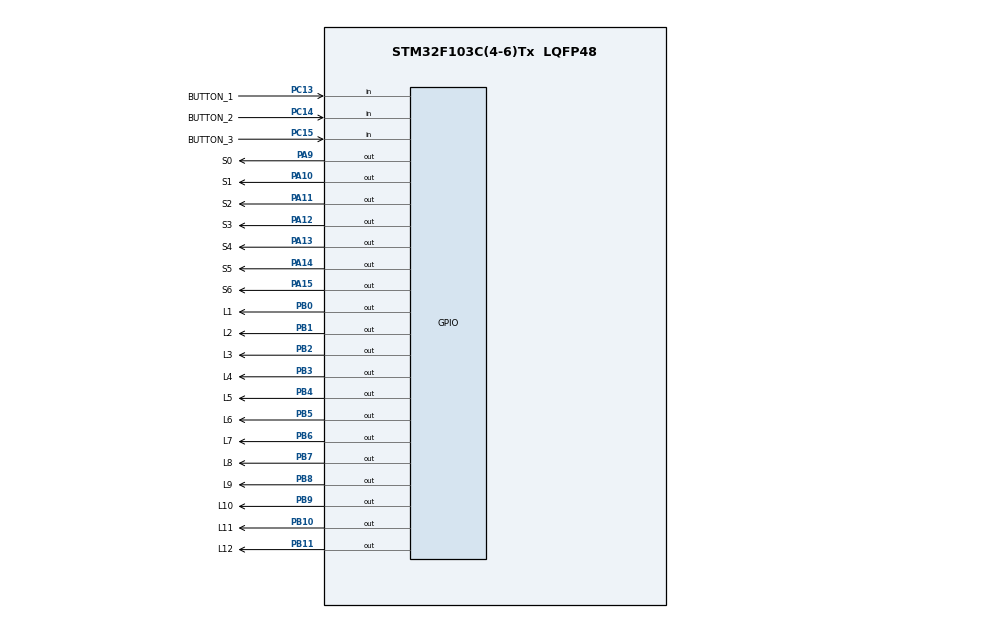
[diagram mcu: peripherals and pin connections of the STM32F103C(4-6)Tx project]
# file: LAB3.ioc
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Mcu.Family=STM32F1
Mcu.Name=STM32F103C(4-6)Tx
Mcu.Package=LQFP48
NVIC.PriorityGroup=NVIC_PRIORITYGROUP_4
PA10.GPIO_Label=S1
PA10.Signal=GPIO_Output
PA11.GPIO_Label=S2
PA11.Signal=GPIO_Output
PA12.GPIO_Label=S3
PA12.Signal=GPIO_Output
PA13.GPIO_Label=S4
PA13.Signal=GPIO_Output
PA14.GPIO_Label=S5
PA14.Signal=GPIO_Output
PA15.GPIO_Label=S6
PA15.Signal=GPIO_Output
PA9.GPIO_Label=S0
PA9.Signal=GPIO_Output
PB0.GPIO_Label=L1
PB0.Signal=GPIO_Output
PB1.GPIO_Label=L2
PB1.Signal=GPIO_Output
PB10.GPIO_Label=L11
PB10.Signal=GPIO_Output
PB11.GPIO_Label=L12
PB11.Signal=GPIO_Output
PB2.GPIO_Label=L3
PB2.Signal=GPIO_Output
PB3.GPIO_Label=L4
PB3.Signal=GPIO_Output
PB4.GPIO_Label=L5
PB4.Signal=GPIO_Output
PB5.GPIO_Label=L6
PB5.Signal=GPIO_Output
PB6.GPIO_Label=L7
PB6.Signal=GPIO_Output
PB7.GPIO_Label=L8
PB7.Signal=GPIO_Output
PB8.GPIO_Label=L9
PB8.Signal=GPIO_Output
PB9.GPIO_Label=L10
PB9.Signal=GPIO_Output
PC13-TAMPER-RTC.GPIO_Label=BUTTON_1
PC13-TAMPER-RTC.GPIO_PuPd=GPIO_PULLUP
PC13-TAMPER-RTC.Signal=GPIO_Input
PC14-OSC32_IN.GPIO_Label=BUTTON_2
PC14-OSC32_IN.GPIO_PuPd=GPIO_PULLUP
PC14-OSC32_IN.Signal=GPIO_Input
PC15-OSC32_OUT.GPIO_Label=BUTTON_3
PC15-OSC32_OUT.GPIO_PuPd=GPIO_PULLUP
PC15-OSC32_OUT.Signal=GPIO_Input
ProjectManager.HeapSize=0x200
ProjectManager.StackSize=0x400
ProjectManager.TargetToolchain=STM32CubeIDE
RCC.APB1Freq_Value=8000000
RCC.APB2Freq_Value=8000000
VP_SYS_VS_ND.Mode=No_Debug
board=custom

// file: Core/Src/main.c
/* USER CODE BEGIN Header */
/**
  ******************************************************************************
  * @file           : main.c
  * @brief          : Main program body
  ******************************************************************************
  * @attention
  *
  * <h2><center>&copy; Copyright (c) 2024 STMicroelectronics.
  * All rights reserved.</center></h2>
  *
  * This software component is licensed by ST under BSD 3-Clause license,
  * the "License"; You may not use this file except in compliance with the
  * License. You may obtain a copy of the License at:
  *                        opensource.org/licenses/BSD-3-Clause
  *
  ******************************************************************************
  */
/* USER CODE END Header */
#include "main.h"

/* USER CODE BEGIN Includes */
#include "button.h"

/* USER CODE END Includes */

void SystemClock_Config(void);
static void MX_GPIO_Init(void);

int main(void)
{

  /* MCU Configuration--------------------------------------------------------*/

  /* Reset of all peripherals, Initializes the Flash interface and the Systick. */
  HAL_Init();

  /* Configure the system clock */
  SystemClock_Config();

  /* Initialize all configured peripherals */
  MX_GPIO_Init();

  /* Infinite loop */
  while (1)
  {

  }
}

void SystemClock_Config(void)
{
  RCC_OscInitTypeDef RCC_OscInitStruct = {0};
  RCC_ClkInitTypeDef RCC_ClkInitStruct = {0};

  /** Initializes the RCC Oscillators according to the specified parameters
  * in the RCC_OscInitTypeDef structure.
  */
  RCC_OscInitStruct.OscillatorType = RCC_OSCILLATORTYPE_HSI;
  RCC_OscInitStruct.HSIState = RCC_HSI_ON;
  RCC_OscInitStruct.HSICalibrationValue = RCC_HSICALIBRATION_DEFAULT;
  RCC_OscInitStruct.PLL.PLLState = RCC_PLL_NONE;
  if (HAL_RCC_OscConfig(&RCC_OscInitStruct) != HAL_OK)
  {
    Error_Handler();
  }
  /** Initializes the CPU, AHB and APB buses clocks
  */
  RCC_ClkInitStruct.ClockType = RCC_CLOCKTYPE_HCLK|RCC_CLOCKTYPE_SYSCLK
                              |RCC_CLOCKTYPE_PCLK1|RCC_CLOCKTYPE_PCLK2;
  RCC_ClkInitStruct.SYSCLKSource = RCC_SYSCLKSOURCE_HSI;
  RCC_ClkInitStruct.AHBCLKDivider = RCC_SYSCLK_DIV1;
  RCC_ClkInitStruct.APB1CLKDivider = RCC_HCLK_DIV1;
  RCC_ClkInitStruct.APB2CLKDivider = RCC_HCLK_DIV1;

  if (HAL_RCC_ClockConfig(&RCC_ClkInitStruct, FLASH_LATENCY_0) != HAL_OK)
  {
    Error_Handler();
  }
}

static void MX_GPIO_Init(void)
{
  GPIO_InitTypeDef GPIO_InitStruct = {0};

  /* GPIO Ports Clock Enable */
  __HAL_RCC_GPIOC_CLK_ENABLE();
  __HAL_RCC_GPIOB_CLK_ENABLE();
  __HAL_RCC_GPIOA_CLK_ENABLE();

  /*Configure GPIO pin Output Level */
  HAL_GPIO_WritePin(GPIOB, L1_Pin|L2_Pin|L3_Pin|L11_Pin
                          |L12_Pin|L4_Pin|L5_Pin|L6_Pin
                          |L7_Pin|L8_Pin|L9_Pin|L10_Pin, GPIO_PIN_RESET);

  /*Configure GPIO pin Output Level */
  HAL_GPIO_WritePin(GPIOA, S0_Pin|S1_Pin|S2_Pin|S3_Pin
                          |S4_Pin|S5_Pin|S6_Pin, GPIO_PIN_RESET);

  /*Configure GPIO pins : BUTTON_1_Pin BUTTON_2_Pin BUTTON_3_Pin */
  GPIO_InitStruct.Pin = BUTTON_1_Pin|BUTTON_2_Pin|BUTTON_3_Pin;
  GPIO_InitStruct.Mode = GPIO_MODE_INPUT;
  GPIO_InitStruct.Pull = GPIO_PULLUP;
  HAL_GPIO_Init(GPIOC, &GPIO_InitStruct);

  /*Configure GPIO pins : L1_Pin L2_Pin L3_Pin L11_Pin
                           L12_Pin L4_Pin L5_Pin L6_Pin
                           L7_Pin L8_Pin L9_Pin L10_Pin */
  GPIO_InitStruct.Pin = L1_Pin|L2_Pin|L3_Pin|L11_Pin
                          |L12_Pin|L4_Pin|L5_Pin|L6_Pin
                          |L7_Pin|L8_Pin|L9_Pin|L10_Pin;
  GPIO_InitStruct.Mode = GPIO_MODE_OUTPUT_PP;
  GPIO_InitStruct.Pull = GPIO_NOPULL;
  GPIO_InitStruct.Speed = GPIO_SPEED_FREQ_LOW;
  HAL_GPIO_Init(GPIOB, &GPIO_InitStruct);

  /*Configure GPIO pins : S0_Pin S1_Pin S2_Pin S3_Pin
                           S4_Pin S5_Pin S6_Pin */
  GPIO_InitStruct.Pin = S0_Pin|S1_Pin|S2_Pin|S3_Pin
                          |S4_Pin|S5_Pin|S6_Pin;
  GPIO_InitStruct.Mode = GPIO_MODE_OUTPUT_PP;
  GPIO_InitStruct.Pull = GPIO_NOPULL;
  GPIO_InitStruct.Speed = GPIO_SPEED_FREQ_LOW;
  HAL_GPIO_Init(GPIOA, &GPIO_InitStruct);

}

void Error_Handler(void)
{
  __disable_irq();
  while (1)
  {
  }
}

/************************ (C) COPYRIGHT STMicroelectronics *****END OF FILE****/
